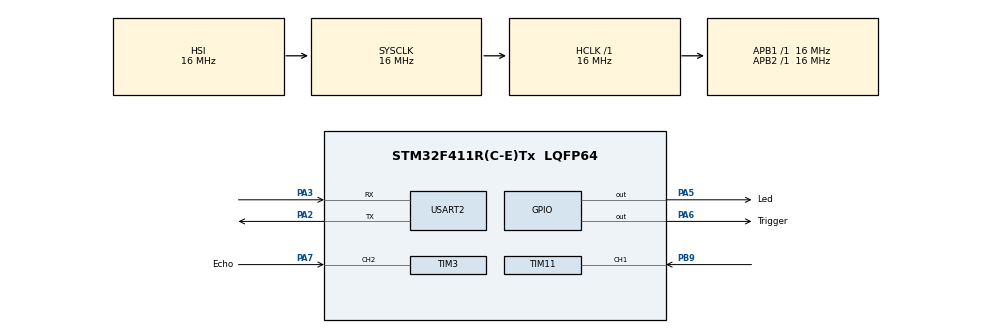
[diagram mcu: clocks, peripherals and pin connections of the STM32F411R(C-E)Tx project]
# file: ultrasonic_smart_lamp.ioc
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Mcu.Family=STM32F4
Mcu.Name=STM32F411R(C-E)Tx
Mcu.Package=LQFP64
NVIC.PriorityGroup=NVIC_PRIORITYGROUP_4
NVIC.TIM3_IRQn=true\:0\:0\:false\:false\:true\:true\:true\:true
PA13.Mode=Serial_Wire
PA13.Signal=SYS_JTMS-SWDIO
PA14.Mode=Serial_Wire
PA14.Signal=SYS_JTCK-SWCLK
PA2.Mode=Asynchronous
PA2.Signal=USART2_TX
PA3.Mode=Asynchronous
PA3.Signal=USART2_RX
PA5.GPIO_Label=Led
PA5.Signal=GPIO_Output
PA6.GPIO_Label=Trigger
PA6.Signal=GPIO_Output
PA7.GPIO_Label=Echo
PA7.Signal=S_TIM3_CH2
PB9.Signal=S_TIM11_CH1
ProjectManager.HeapSize=0x200
ProjectManager.StackSize=0x400
ProjectManager.TargetToolchain=STM32CubeIDE
RCC.AHBFreq_Value=16000000
RCC.APB1Freq_Value=16000000
RCC.APB2Freq_Value=16000000
RCC.CortexFreq_Value=16000000
RCC.HSE_VALUE=25000000
RCC.HSI_VALUE=16000000
RCC.LSE_VALUE=32768
RCC.SYSCLKFreq_VALUE=16000000
RCC.VCOOutputFreq_Value=192000000
SH.S_TIM11_CH1.0=TIM11_CH1,Input_Capture1_from_TI1
SH.S_TIM3_CH2.0=TIM3_CH2,Input_Capture2_from_TI2
TIM11.Channel=TIM_CHANNEL_1
TIM3.Channel-Input_Capture2_from_TI2=TIM_CHANNEL_2
TIM3.Prescaler=16-1
USART2.VirtualMode=VM_ASYNC
VP_TIM11_VS_ClockSourceINT.Mode=Enable_Timer
VP_TIM3_VS_ClockSourceINT.Mode=Internal
board=custom

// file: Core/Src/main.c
/* USER CODE BEGIN Header */
/**
  ******************************************************************************
  * @file           : main.c
  * @brief          : Main program body
  ******************************************************************************
  * @attention
  *
  * Copyright (c) 2024 STMicroelectronics.
  * All rights reserved.
  *
  * This software is licensed under terms that can be found in the LICENSE file
  * in the root directory of this software component.
  * If no LICENSE file comes with this software, it is provided AS-IS.
  *
  ******************************************************************************
  */
/* USER CODE END Header */
#include "main.h"
#include "app.h"

TIM_HandleTypeDef htim3;
TIM_HandleTypeDef htim11;

UART_HandleTypeDef huart2;

/* USER CODE BEGIN PV */
int ledTimer10s=0;
int gt5 = 0;
int lt5 = 0;
/* USER CODE END PV */

void SystemClock_Config(void);
static void MX_GPIO_Init(void);
static void MX_TIM11_Init(void);
static void MX_TIM3_Init(void);
static void MX_USART2_UART_Init(void);

/* USER CODE BEGIN 0 */

void SystickCallback(){
	if(gt5==1){
		lt5 = 0;
		ledTimer10s++;
	}

	if(lt5==1){
		gt5 = 0;
		ledTimer10s=0;
	}
}
/* USER CODE END 0 */

int main(void)
{

  /* MCU Configuration--------------------------------------------------------*/

  /* Reset of all peripherals, Initializes the Flash interface and the Systick. */
  HAL_Init();

  /* Configure the system clock */
  SystemClock_Config();

  /* Initialize all configured peripherals */
  MX_GPIO_Init();
  MX_TIM11_Init();
  MX_TIM3_Init();
  MX_USART2_UART_Init();
  /* USER CODE BEGIN 2 */
  app();
  /* USER CODE END 2 */

  /* Infinite loop */
  while (1)
  {

  }
}

void SystemClock_Config(void)
{
  RCC_OscInitTypeDef RCC_OscInitStruct = {0};
  RCC_ClkInitTypeDef RCC_ClkInitStruct = {0};

  /** Configure the main internal regulator output voltage
  */
  __HAL_RCC_PWR_CLK_ENABLE();
  __HAL_PWR_VOLTAGESCALING_CONFIG(PWR_REGULATOR_VOLTAGE_SCALE1);

  /** Initializes the RCC Oscillators according to the specified parameters
  * in the RCC_OscInitTypeDef structure.
  */
  RCC_OscInitStruct.OscillatorType = RCC_OSCILLATORTYPE_HSI;
  RCC_OscInitStruct.HSIState = RCC_HSI_ON;
  RCC_OscInitStruct.HSICalibrationValue = RCC_HSICALIBRATION_DEFAULT;
  RCC_OscInitStruct.PLL.PLLState = RCC_PLL_NONE;
  if (HAL_RCC_OscConfig(&RCC_OscInitStruct) != HAL_OK)
  {
    Error_Handler();
  }

  /** Initializes the CPU, AHB and APB buses clocks
  */
  RCC_ClkInitStruct.ClockType = RCC_CLOCKTYPE_HCLK|RCC_CLOCKTYPE_SYSCLK
                              |RCC_CLOCKTYPE_PCLK1|RCC_CLOCKTYPE_PCLK2;
  RCC_ClkInitStruct.SYSCLKSource = RCC_SYSCLKSOURCE_HSI;
  RCC_ClkInitStruct.AHBCLKDivider = RCC_SYSCLK_DIV1;
  RCC_ClkInitStruct.APB1CLKDivider = RCC_HCLK_DIV1;
  RCC_ClkInitStruct.APB2CLKDivider = RCC_HCLK_DIV1;

  if (HAL_RCC_ClockConfig(&RCC_ClkInitStruct, FLASH_LATENCY_0) != HAL_OK)
  {
    Error_Handler();
  }
}

static void MX_TIM3_Init(void)
{

  TIM_ClockConfigTypeDef sClockSourceConfig = {0};
  TIM_MasterConfigTypeDef sMasterConfig = {0};
  TIM_IC_InitTypeDef sConfigIC = {0};

  htim3.Instance = TIM3;
  htim3.Init.Prescaler = 16-1;
  htim3.Init.CounterMode = TIM_COUNTERMODE_UP;
  htim3.Init.Period = 65535;
  htim3.Init.ClockDivision = TIM_CLOCKDIVISION_DIV1;
  htim3.Init.AutoReloadPreload = TIM_AUTORELOAD_PRELOAD_DISABLE;
  if (HAL_TIM_Base_Init(&htim3) != HAL_OK)
  {
    Error_Handler();
  }
  sClockSourceConfig.ClockSource = TIM_CLOCKSOURCE_INTERNAL;
  if (HAL_TIM_ConfigClockSource(&htim3, &sClockSourceConfig) != HAL_OK)
  {
    Error_Handler();
  }
  if (HAL_TIM_IC_Init(&htim3) != HAL_OK)
  {
    Error_Handler();
  }
  sMasterConfig.MasterOutputTrigger = TIM_TRGO_RESET;
  sMasterConfig.MasterSlaveMode = TIM_MASTERSLAVEMODE_DISABLE;
  if (HAL_TIMEx_MasterConfigSynchronization(&htim3, &sMasterConfig) != HAL_OK)
  {
    Error_Handler();
  }
  sConfigIC.ICPolarity = TIM_INPUTCHANNELPOLARITY_RISING;
  sConfigIC.ICSelection = TIM_ICSELECTION_DIRECTTI;
  sConfigIC.ICPrescaler = TIM_ICPSC_DIV1;
  sConfigIC.ICFilter = 0;
  if (HAL_TIM_IC_ConfigChannel(&htim3, &sConfigIC, TIM_CHANNEL_2) != HAL_OK)
  {
    Error_Handler();
  }

}

static void MX_TIM11_Init(void)
{

  TIM_IC_InitTypeDef sConfigIC = {0};

  htim11.Instance = TIM11;
  htim11.Init.Prescaler = 0;
  htim11.Init.CounterMode = TIM_COUNTERMODE_UP;
  htim11.Init.Period = 65535;
  htim11.Init.ClockDivision = TIM_CLOCKDIVISION_DIV1;
  htim11.Init.AutoReloadPreload = TIM_AUTORELOAD_PRELOAD_DISABLE;
  if (HAL_TIM_Base_Init(&htim11) != HAL_OK)
  {
    Error_Handler();
  }
  if (HAL_TIM_IC_Init(&htim11) != HAL_OK)
  {
    Error_Handler();
  }
  sConfigIC.ICPolarity = TIM_INPUTCHANNELPOLARITY_RISING;
  sConfigIC.ICSelection = TIM_ICSELECTION_DIRECTTI;
  sConfigIC.ICPrescaler = TIM_ICPSC_DIV1;
  sConfigIC.ICFilter = 0;
  if (HAL_TIM_IC_ConfigChannel(&htim11, &sConfigIC, TIM_CHANNEL_1) != HAL_OK)
  {
    Error_Handler();
  }

}

static void MX_USART2_UART_Init(void)
{

  huart2.Instance = USART2;
  huart2.Init.BaudRate = 115200;
  huart2.Init.WordLength = UART_WORDLENGTH_8B;
  huart2.Init.StopBits = UART_STOPBITS_1;
  huart2.Init.Parity = UART_PARITY_NONE;
  huart2.Init.Mode = UART_MODE_TX_RX;
  huart2.Init.HwFlowCtl = UART_HWCONTROL_NONE;
  huart2.Init.OverSampling = UART_OVERSAMPLING_16;
  if (HAL_UART_Init(&huart2) != HAL_OK)
  {
    Error_Handler();
  }

}

static void MX_GPIO_Init(void)
{
  GPIO_InitTypeDef GPIO_InitStruct = {0};

  /* GPIO Ports Clock Enable */
  __HAL_RCC_GPIOA_CLK_ENABLE();
  __HAL_RCC_GPIOB_CLK_ENABLE();

  /*Configure GPIO pin Output Level */
  HAL_GPIO_WritePin(GPIOA, Led_Pin|Trigger_Pin, GPIO_PIN_RESET);

  /*Configure GPIO pins : Led_Pin Trigger_Pin */
  GPIO_InitStruct.Pin = Led_Pin|Trigger_Pin;
  GPIO_InitStruct.Mode = GPIO_MODE_OUTPUT_PP;
  GPIO_InitStruct.Pull = GPIO_NOPULL;
  GPIO_InitStruct.Speed = GPIO_SPEED_FREQ_LOW;
  HAL_GPIO_Init(GPIOA, &GPIO_InitStruct);

}

void Error_Handler(void)
{
  __disable_irq();
  while (1)
  {
  }
}
